# STM32G4xx register map
File version: 1.3
CPU: CM4 r0p1, little endian, MPU, FPU, 4 interrupt priority bits
Registers are 32-bit, read-write, reset 0x0 unless marked. A register's access mark holds for its fields unless they carry their own. Offsets are from the block's base; [hi:lo] are bit positions; {n}, {i} and the like mark numbered series.

## SYSCFG_VREFBUF_COMP — System configuration controller_Voltage reference buffer_COMP
Base 0x40010000
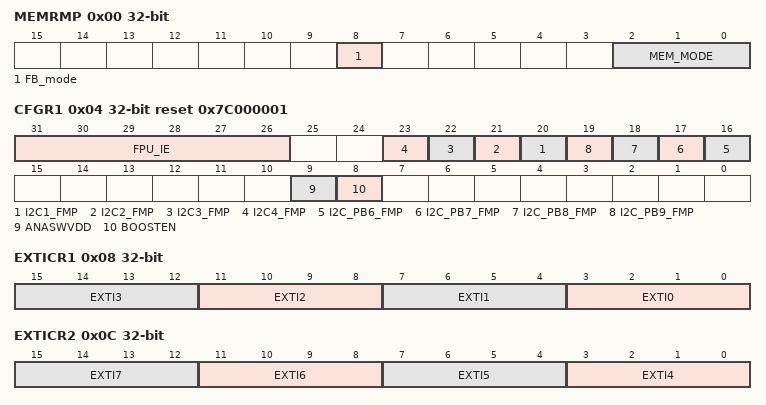
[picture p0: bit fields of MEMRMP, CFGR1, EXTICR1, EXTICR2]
0x00 MEMRMP — Remap Memory register
  [8] FB_mode — User Flash Bank mode
  [2:0] MEM_MODE — Memory mapping selection
0x04 CFGR1 reset 0x7C000001 — peripheral mode configuration register
  [31:26] FPU_IE — FPU Interrupts Enable
  [n+19] I2C{n}_FMP (n=1..4) — I2C1 FM+ drive capability enable
  [n+10] I2C_PB{n}_FMP (n=6..9) — FM+ drive capability on PB6
  [9] ANASWVDD — GPIO analog switch control voltage selection
  [8] BOOSTEN
0x08 EXTICR1 — external interrupt configuration register 1
  [4n+3:4n] EXTI{n} (n=0..3) — EXTI x configuration (x = 0 to 3)
0x0C EXTICR2 — external interrupt configuration register 2
  [4n-13:4n-16] EXTI{n} (n=4..7) — EXTI x configuration (x = 4 to 7)
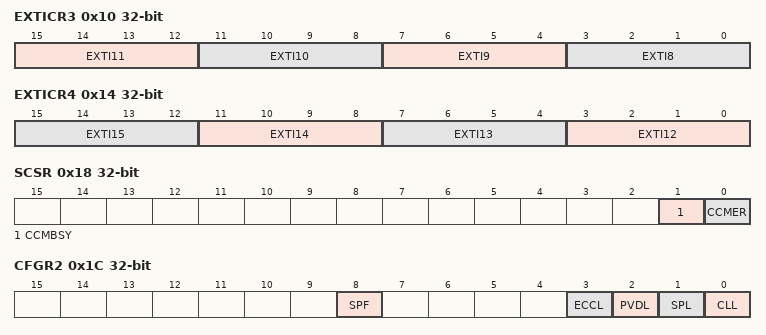
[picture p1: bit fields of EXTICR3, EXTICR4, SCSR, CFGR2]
0x10 EXTICR3 — external interrupt configuration register 3
  [15:12] EXTI11 — EXTI x configuration (x = 8 to 11)
  [11:8] EXTI10
  [7:4] EXTI9 — EXTI x configuration (x = 8 to 11)
  [3:0] EXTI8 — EXTI x configuration (x = 8 to 11)
0x14 EXTICR4 — external interrupt configuration register 4
  [4n-45:4n-48] EXTI{n} (n=12..15) — EXTI x configuration (x = 12 to 15)
0x18 SCSR access per field — CCM SRAM control and status register
  [1] CCMBSY ro — CCM SRAM busy by erase operation
  [0] CCMER rw — CCM SRAM Erase
0x1C CFGR2 — configuration register 2
  [8] SPF — SRAM Parity Flag
  [3] ECCL — ECC Lock
  [2] PVDL — PVD Lock
  [1] SPL — SRAM Parity Lock
  [0] CLL — Core Lockup Lock
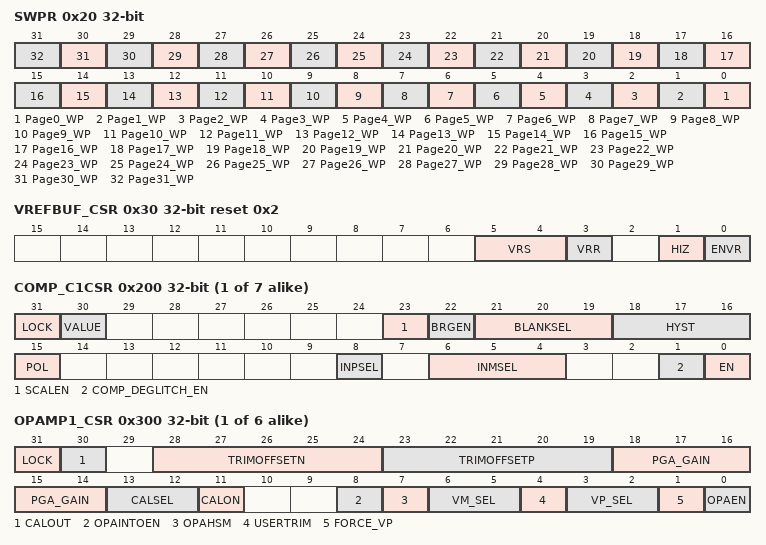
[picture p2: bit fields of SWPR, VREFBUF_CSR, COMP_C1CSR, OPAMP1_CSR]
0x20 SWPR — SRAM Write protection register 1
  [n] Page{n}_WP (n=0..31) — Write protection
0x24 SKR wo — SRAM2 Key Register
  [7:0] KEY — SRAM2 Key for software erase
0x30 VREFBUF_CSR access per field reset 0x2 — VREF_BUF Control and Status Register
  [5:4] VRS rw — Voltage reference scale
  [3] VRR ro — Voltage reference buffer ready
  [1] HIZ rw — High impedence mode for the VREF_BUF
  [0] ENVR rw — Enable Voltage Reference
0x34 VREFBUF_CCR — VREF_BUF Calibration Control Register
  [5:0] TRIM — Trimming code
{0x1FC+4i} COMP_C{i}CSR access per field (i=1..7) — Comparator control/status register
  [31] LOCK rw, [30] VALUE ro, [23] SCALEN rw, [22] BRGEN rw, [21:19] BLANKSEL rw, [18:16] HYST rw, [15] POL rw, [8] INPSEL rw, [6:4] INMSEL rw, [1] COMP_DEGLITCH_EN rw, [0] EN rw
{0x2FC+4i} OPAMP{i}_CSR (i=1..6) — OPAMP{i} control/status register
  [31] LOCK
  [30] CALOUT
  [28:24] TRIMOFFSETN
  [23:19] TRIMOFFSETP
  [18:14] PGA_GAIN
  [13:12] CALSEL
  [11] CALON
  [8] OPAINTOEN
  [7] OPAHSM
  [6:5] VM_SEL
  [4] USERTRIM
  [3:2] VP_SEL
  [1] FORCE_VP
  [0] OPAEN — Operational amplifier Enable
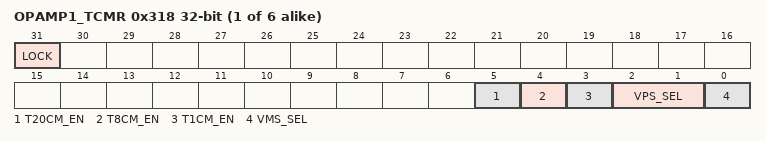
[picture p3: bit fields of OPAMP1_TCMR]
{0x314+4i} OPAMP{i}_TCMR (i=1..6) — OPAMP{i} control/status register
  [31] LOCK, [5] T20CM_EN, [4] T8CM_EN, [3] T1CM_EN, [2:1] VPS_SEL, [0] VMS_SEL

## HRTIM_Master — High Resolution Timer: Master Timers
Base 0x40016800
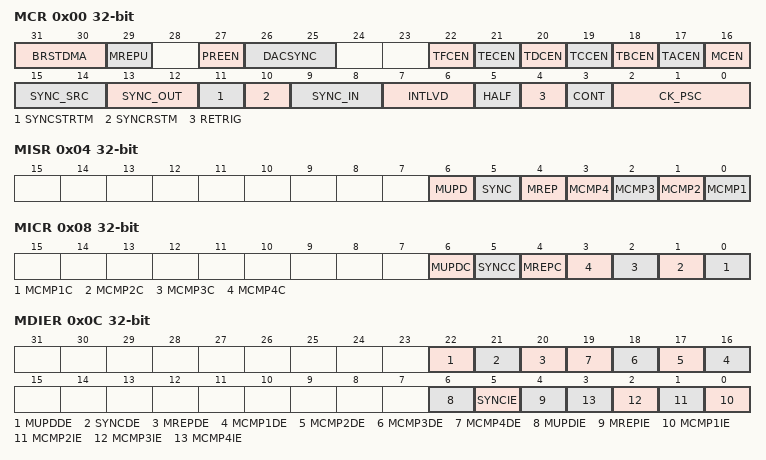
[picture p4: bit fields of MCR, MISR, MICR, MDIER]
0x00 MCR — Master Timer Control Register
  [31:30] BRSTDMA — Burst DMA Update
  [29] MREPU — Master Timer Repetition update
  [27] PREEN — Preload enable
  [26:25] DACSYNC — AC Synchronization
  [22] TFCEN — Timer F counter enable
  [21] TECEN — Timer E counter enable
  [20] TDCEN — Timer D counter enable
  [19] TCCEN — Timer C counter enable
  [18] TBCEN — Timer B counter enable
  [17] TACEN — Timer A counter enable
  [16] MCEN — Master Counter enable
  [15:14] SYNC_SRC — Synchronization source
  [13:12] SYNC_OUT — Synchronization output
  [11] SYNCSTRTM — Synchronization Starts Master
  [10] SYNCRSTM — Synchronization Resets Master
  [9:8] SYNC_IN — synchronization input
  [7:6] INTLVD — Interleaved mode
  [5] HALF — Half mode enable
  [4] RETRIG — Master Re-triggerable mode
  [3] CONT — Master Continuous mode
  [2:0] CK_PSC — HRTIM Master Clock prescaler
0x04 MISR ro — Master Timer Interrupt Status Register
  [6] MUPD — Master Update Interrupt Flag
  [5] SYNC — Sync Input Interrupt Flag
  [4] MREP — Master Repetition Interrupt Flag
  [n-1] MCMP{n} (n=1..4) — Master Compare {n} Interrupt Flag
0x08 MICR wo — Master Timer Interrupt Clear Register
  [6] MUPDC — Master update Interrupt flag clear
  [5] SYNCC — Sync Input Interrupt flag clear
  [4] MREPC — Repetition Interrupt flag clear
  [n-1] MCMP{n}C (n=1..4) — Master Compare {n} Interrupt flag clear
0x0C MDIER — HRTIM Master Timer DMA / Interrupt Enable Register
  [22] MUPDDE, [21] SYNCDE, [20] MREPDE, [n+15] MCMP{n}DE (n=1..4), [6] MUPDIE, [5] SYNCIE, [4] MREPIE, [n-1] MCMP{n}IE (n=1..4)
0x10 MCNTR — Master Timer Counter Register
  [15:0] MCNT — Counter value
0x14 MPER reset 0xFFFF — Master Timer Period Register
  [15:0] MPER — Master Timer Period value
0x18 MREP — Master Timer Repetition Register
  [7:0] MREP — Master Timer Repetition counter value
0x1C MCMP1R — Master Timer Compare 1 Register
  [15:0] MCMP1 — Master Timer Compare 1 value
{0x1C+4i} MCMP{i}R (i=2..4) — Master Timer Compare {i} Register
  [15:0] MCMP{i} — Master Timer Compare {i} value
